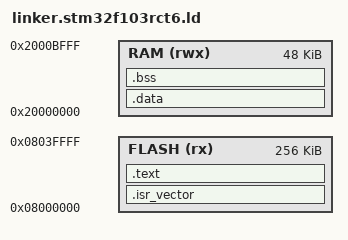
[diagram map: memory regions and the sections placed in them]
MEMORY
{
    FLASH (rx)  : ORIGIN = 0x08000000, LENGTH = 256K
    RAM   (rwx) : ORIGIN = 0x20000000, LENGTH = 48K
}

_estack = ORIGIN(RAM) + LENGTH(RAM);

SECTIONS
{
    .isr_vector :
    {
        KEEP(*(.isr_vector))
    } > FLASH

    .text :
    {
        *(.text*)
        *(.rodata*)
        KEEP(*(.init))
        KEEP(*(.fini))
        . = ALIGN(4);
        _etext = .;
    } > FLASH

    .data : AT(_etext)
    {
        . = ALIGN(4);
        _sdata = .;
        *(.data*)
        . = ALIGN(4);
        _edata = .;
    } > RAM

    _sidata = LOADADDR(.data);

    .bss :
    {
        . = ALIGN(4);
        _sbss = .;
        *(.bss*)
        *(COMMON)
        . = ALIGN(4);
        _ebss = .;
    } > RAM

    . = ALIGN(4);
    _end = .;
}
